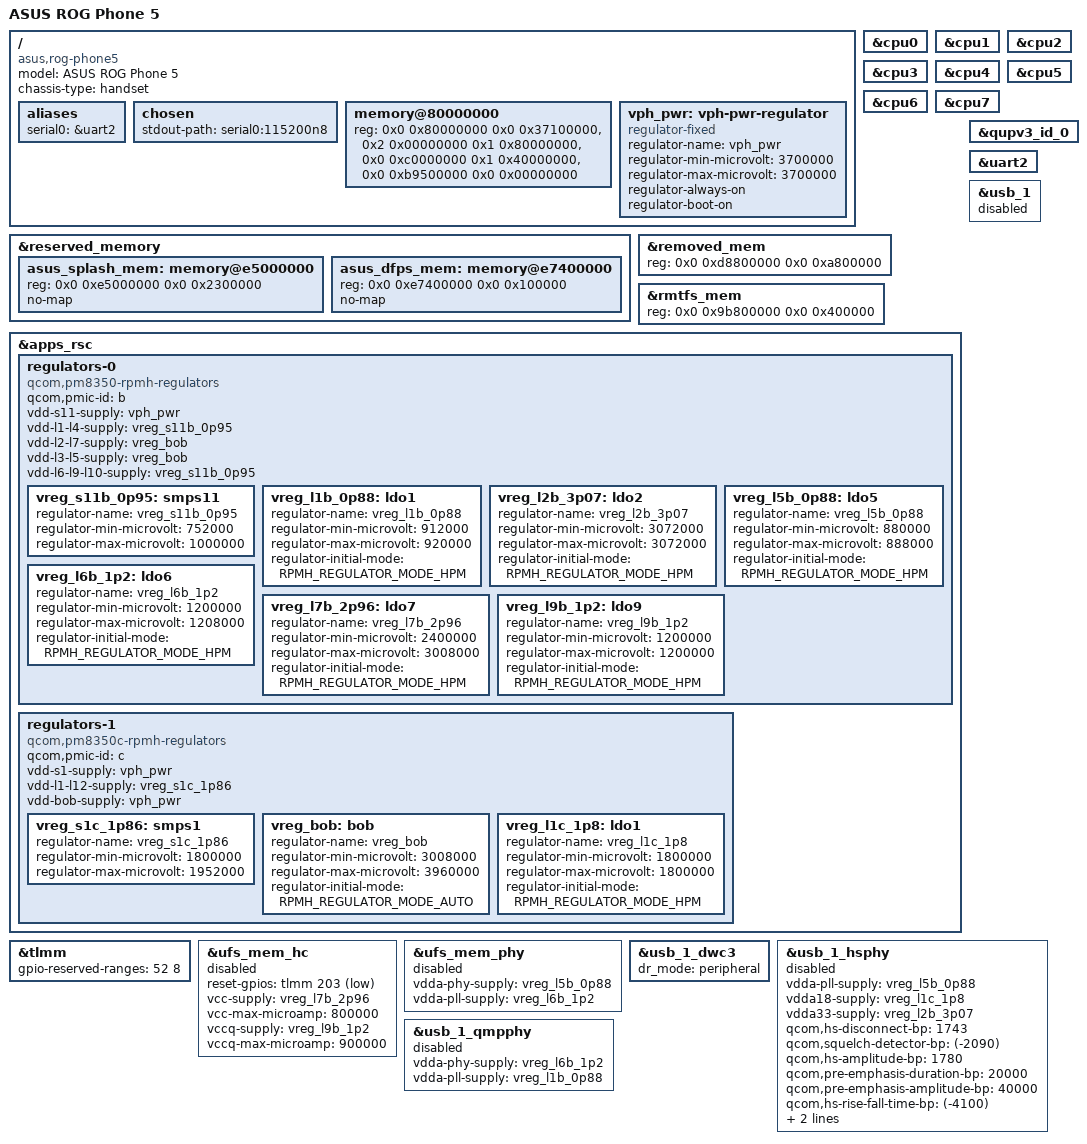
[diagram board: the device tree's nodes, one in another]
// SPDX-License-Identifier: BSD-3-Clause
/dts-v1/;

#include <dt-bindings/regulator/qcom,rpmh-regulator.h>
#include "sm8350.dtsi"
#include "pm8350.dtsi"
#include "pm8350b.dtsi"
#include "pm8350c.dtsi"
#include "pmk8350.dtsi"
#include "pmr735a.dtsi"
#include "pmr735b.dtsi"

/ {
	model = "ASUS ROG Phone 5";
	compatible = "asus,rog-phone5", "qcom,sm8350";
	chassis-type = "handset";

	aliases {
		serial0 = &uart2;
	};

	chosen {
		stdout-path = "serial0:115200n8";
	};

	memory@80000000 {
		device_type = "memory";
		reg = <0x0 0x80000000 0x0 0x37100000>,
		      <0x2 0x00000000 0x1 0x80000000>,
		      <0x0 0xc0000000 0x1 0x40000000>,
		      <0x0 0xb9500000 0x0 0x00000000>;
	};

	vph_pwr: vph-pwr-regulator {
		compatible = "regulator-fixed";
		regulator-name = "vph_pwr";
		regulator-min-microvolt = <3700000>;
		regulator-max-microvolt = <3700000>;
		regulator-always-on;
		regulator-boot-on;
	};
};

/* Board deltas from the upstream SM8350 fixed reservation map. */
&reserved_memory {
	asus_splash_mem: memory@e5000000 {
		reg = <0x0 0xe5000000 0x0 0x2300000>;
		no-map;
	};

	asus_dfps_mem: memory@e7400000 {
		reg = <0x0 0xe7400000 0x0 0x100000>;
		no-map;
	};
};

/*
 * ASUS firmware resets when Linux switches the hierarchical PSCI topology
 * into OSI mode after kexec.  Keep the CPUs on ordinary PSCI/WFI until that
 * firmware quirk is handled, and avoid dangling references to the disabled
 * CPU-idle domain providers.
 */
&cpu0 {
	/delete-property/ power-domains;
	/delete-property/ power-domain-names;
};

&cpu1 {
	/delete-property/ power-domains;
	/delete-property/ power-domain-names;
};

&cpu2 {
	/delete-property/ power-domains;
	/delete-property/ power-domain-names;
};

&cpu3 {
	/delete-property/ power-domains;
	/delete-property/ power-domain-names;
};

&cpu4 {
	/delete-property/ power-domains;
	/delete-property/ power-domain-names;
};

&cpu5 {
	/delete-property/ power-domains;
	/delete-property/ power-domain-names;
};

&cpu6 {
	/delete-property/ power-domains;
	/delete-property/ power-domain-names;
};

&cpu7 {
	/delete-property/ power-domains;
	/delete-property/ power-domain-names;
};

/* The vendor board reserves a larger safety/debug span at these labels. */
&removed_mem {
	reg = <0x0 0xd8800000 0x0 0xa800000>;
};

&rmtfs_mem {
	reg = <0x0 0x9b800000 0x0 0x400000>;
};

/*
 * Only rails required by the disabled UFS and USB recovery tiers are here.
 * ASUS vendor rail identities and voltage ranges match the upstream SM8350
 * references; both subsystems remain disabled until recovery gates exist.
 */
&apps_rsc {
	/delete-property/ power-domains;

	regulators-0 {
		compatible = "qcom,pm8350-rpmh-regulators";
		qcom,pmic-id = "b";

		vdd-s11-supply = <&vph_pwr>;
		vdd-l1-l4-supply = <&vreg_s11b_0p95>;
		vdd-l2-l7-supply = <&vreg_bob>;
		vdd-l3-l5-supply = <&vreg_bob>;
		vdd-l6-l9-l10-supply = <&vreg_s11b_0p95>;

		vreg_s11b_0p95: smps11 {
			regulator-name = "vreg_s11b_0p95";
			regulator-min-microvolt = <752000>;
			regulator-max-microvolt = <1000000>;
		};

		vreg_l1b_0p88: ldo1 {
			regulator-name = "vreg_l1b_0p88";
			regulator-min-microvolt = <912000>;
			regulator-max-microvolt = <920000>;
			regulator-initial-mode = <RPMH_REGULATOR_MODE_HPM>;
		};

		vreg_l2b_3p07: ldo2 {
			regulator-name = "vreg_l2b_3p07";
			regulator-min-microvolt = <3072000>;
			regulator-max-microvolt = <3072000>;
			regulator-initial-mode = <RPMH_REGULATOR_MODE_HPM>;
		};

		vreg_l5b_0p88: ldo5 {
			regulator-name = "vreg_l5b_0p88";
			regulator-min-microvolt = <880000>;
			regulator-max-microvolt = <888000>;
			regulator-initial-mode = <RPMH_REGULATOR_MODE_HPM>;
		};

		vreg_l6b_1p2: ldo6 {
			regulator-name = "vreg_l6b_1p2";
			regulator-min-microvolt = <1200000>;
			regulator-max-microvolt = <1208000>;
			regulator-initial-mode = <RPMH_REGULATOR_MODE_HPM>;
		};

		vreg_l7b_2p96: ldo7 {
			regulator-name = "vreg_l7b_2p96";
			regulator-min-microvolt = <2400000>;
			regulator-max-microvolt = <3008000>;
			regulator-initial-mode = <RPMH_REGULATOR_MODE_HPM>;
		};

		vreg_l9b_1p2: ldo9 {
			regulator-name = "vreg_l9b_1p2";
			regulator-min-microvolt = <1200000>;
			regulator-max-microvolt = <1200000>;
			regulator-initial-mode = <RPMH_REGULATOR_MODE_HPM>;
		};
	};

	regulators-1 {
		compatible = "qcom,pm8350c-rpmh-regulators";
		qcom,pmic-id = "c";

		vdd-s1-supply = <&vph_pwr>;
		vdd-l1-l12-supply = <&vreg_s1c_1p86>;
		vdd-bob-supply = <&vph_pwr>;

		vreg_s1c_1p86: smps1 {
			regulator-name = "vreg_s1c_1p86";
			regulator-min-microvolt = <1800000>;
			regulator-max-microvolt = <1952000>;
		};

		vreg_bob: bob {
			regulator-name = "vreg_bob";
			regulator-min-microvolt = <3008000>;
			regulator-max-microvolt = <3960000>;
			regulator-initial-mode = <RPMH_REGULATOR_MODE_AUTO>;
		};

		vreg_l1c_1p8: ldo1 {
			regulator-name = "vreg_l1c_1p8";
			regulator-min-microvolt = <1800000>;
			regulator-max-microvolt = <1800000>;
			regulator-initial-mode = <RPMH_REGULATOR_MODE_HPM>;
		};
	};
};

/*
 * GPIOs 52-59 are not accessible through TLMM on SM8350. Reserving them
 * keeps gpiolib from reading the absent register page while adding the chip.
 */
&tlmm {
	gpio-reserved-ranges = <52 8>;
};

/* Serial-only skeleton: storage, USB, display, GPU and radios stay disabled. */
&qupv3_id_0 {
	status = "okay";
};

&uart2 {
	status = "okay";
};

&ufs_mem_hc {
	reset-gpios = <&tlmm 203 GPIO_ACTIVE_LOW>;

	vcc-supply = <&vreg_l7b_2p96>;
	vcc-max-microamp = <800000>;
	vccq-supply = <&vreg_l9b_1p2>;
	vccq-max-microamp = <900000>;

	status = "disabled";
};

&ufs_mem_phy {
	vdda-phy-supply = <&vreg_l5b_0p88>;
	vdda-pll-supply = <&vreg_l6b_1p2>;

	status = "disabled";
};

/* usb_1 is the reviewed left-side recovery connector; keep it inert. */
&usb_1 {
	status = "disabled";
};

&usb_1_dwc3 {
	dr_mode = "peripheral";
};

&usb_1_hsphy {
	vdda-pll-supply = <&vreg_l5b_0p88>;
	vdda18-supply = <&vreg_l1c_1p8>;
	vdda33-supply = <&vreg_l2b_3p07>;

	/* ASUS HS-PHY register overrides translated to the upstream binding. */
	qcom,hs-disconnect-bp = <1743>;
	qcom,squelch-detector-bp = <(-2090)>;
	qcom,hs-amplitude-bp = <1780>;
	qcom,pre-emphasis-duration-bp = <20000>;
	qcom,pre-emphasis-amplitude-bp = <40000>;
	qcom,hs-rise-fall-time-bp = <(-4100)>;
	qcom,hs-crossover-voltage-microvolt = <(-31000)>;
	qcom,hs-output-impedance-micro-ohms = <2600000>;

	status = "disabled";
};

&usb_1_qmpphy {
	vdda-phy-supply = <&vreg_l6b_1p2>;
	vdda-pll-supply = <&vreg_l1b_0p88>;

	status = "disabled";
};
